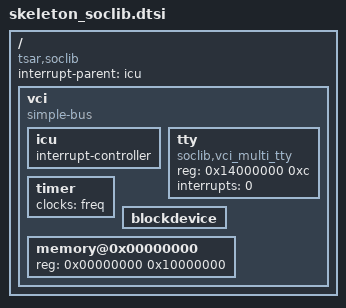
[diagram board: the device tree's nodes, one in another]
/*
 * Skeleton DTS file for TSAR on SoCLib
 */

/include/ "skeleton.dtsi"

/ {
	compatible = "tsar,soclib";
	interrupt-parent = <&icu>;

	vci {
		compatible = "simple-bus";
		#address-cells = <1>;
		#size-cells = <1>;
		ranges; // identity mapping between root addressing and vci network

		icu: icu {
			interrupt-controller;
			#interrupt-cells = <1>;
		};

		tty: tty {
			compatible = "soclib,vci_multi_tty";
			reg = <0x14000000 0xc>;
			interrupts = <0>;
		};

		timer {
			clocks = <&freq>;
		};

		blockdevice {
		};

		/*
		framebuffer {
			compatible = "tsar,vci_framebuffer", "simple-framebuffer";
			reg = <0x20000000 (640 * 680 * 2)>;
			width = <640>;
			height = <480>;
			stride = <(640 * 2)>;
			format = "r5g6b5";
		};
		*/

		memory@0x00000000 {
			device_type = "memory";
			reg = <0x00000000 0x10000000>;
		};
	};
};
